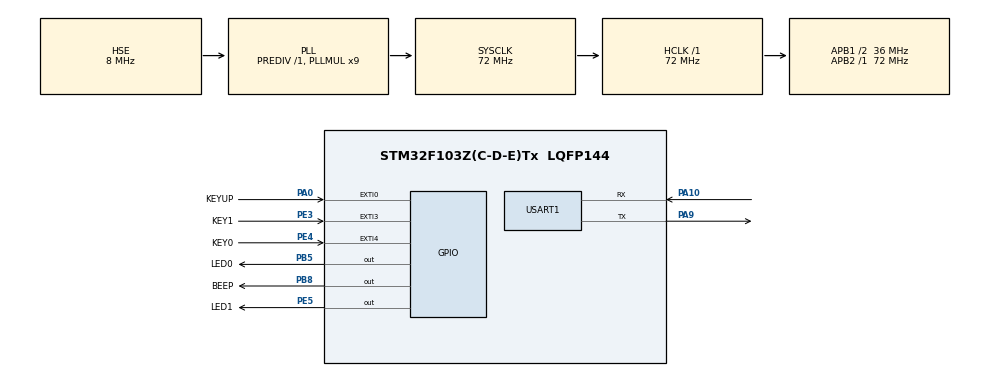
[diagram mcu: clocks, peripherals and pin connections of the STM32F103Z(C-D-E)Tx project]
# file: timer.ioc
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Mcu.Family=STM32F1
Mcu.Name=STM32F103Z(C-D-E)Tx
Mcu.Package=LQFP144
NVIC.EXTI0_IRQn=true\:1\:0\:true\:false\:true\:true\:true
NVIC.EXTI3_IRQn=true\:1\:0\:true\:false\:true\:true\:true
NVIC.EXTI4_IRQn=true\:1\:0\:true\:false\:true\:true\:true
NVIC.PriorityGroup=NVIC_PRIORITYGROUP_4
NVIC.TIM6_IRQn=true\:3\:0\:true\:false\:true\:true\:true
NVIC.TIM7_IRQn=true\:3\:0\:true\:false\:true\:true\:true
NVIC.USART1_IRQn=true\:0\:0\:false\:false\:true\:true\:true
OSC_IN.Mode=HSE-External-Oscillator
OSC_IN.Signal=RCC_OSC_IN
OSC_OUT.Mode=HSE-External-Oscillator
OSC_OUT.Signal=RCC_OSC_OUT
PA0-WKUP.GPIO_Label=KEYUP
PA0-WKUP.GPIO_ModeDefaultEXTI=GPIO_MODE_IT_RISING
PA0-WKUP.GPIO_PuPd=GPIO_PULLDOWN
PA0-WKUP.Signal=GPXTI0
PA10.Mode=Asynchronous
PA10.Signal=USART1_RX
PA13.Mode=Serial_Wire
PA13.Signal=SYS_JTMS-SWDIO
PA14.Mode=Serial_Wire
PA14.Signal=SYS_JTCK-SWCLK
PA9.Mode=Asynchronous
PA9.Signal=USART1_TX
PB5.GPIO_Label=LED0
PB5.PinState=GPIO_PIN_SET
PB5.Signal=GPIO_Output
PB8.GPIO_Label=BEEP
PB8.Signal=GPIO_Output
PE3.GPIO_Label=KEY1
PE3.GPIO_ModeDefaultEXTI=GPIO_MODE_IT_FALLING
PE3.GPIO_PuPd=GPIO_PULLUP
PE3.Signal=GPXTI3
PE4.GPIO_Label=KEY0
PE4.GPIO_ModeDefaultEXTI=GPIO_MODE_IT_FALLING
PE4.GPIO_PuPd=GPIO_PULLUP
PE4.Signal=GPXTI4
PE5.GPIO_Label=LED1
PE5.PinState=GPIO_PIN_SET
PE5.Signal=GPIO_Output
ProjectManager.HeapSize=0x200
ProjectManager.StackSize=0x400
ProjectManager.TargetToolchain=SW4STM32
RCC.AHBFreq_Value=72000000
RCC.APB1CLKDivider=RCC_HCLK_DIV2
RCC.APB1Freq_Value=36000000
RCC.APB1TimFreq_Value=72000000
RCC.APB2Freq_Value=72000000
RCC.APB2TimFreq_Value=72000000
RCC.HCLKFreq_Value=72000000
RCC.PLLMUL=RCC_PLL_MUL9
RCC.PLLSourceVirtual=RCC_PLLSOURCE_HSE
RCC.SYSCLKFreq_VALUE=72000000
RCC.SYSCLKSource=RCC_SYSCLKSOURCE_PLLCLK
RCC.USBFreq_Value=72000000
TIM6.AutoReloadPreload=TIM_AUTORELOAD_PRELOAD_DISABLE
TIM6.Period=10000-1
TIM6.Prescaler=7200-1
TIM7.AutoReloadPreload=TIM_AUTORELOAD_PRELOAD_DISABLE
TIM7.Period=5000-1
TIM7.Prescaler=7200-1
USART1.VirtualMode=VM_ASYNC
VP_TIM6_VS_ClockSourceINT.Mode=Enable_Timer
VP_TIM7_VS_ClockSourceINT.Mode=Enable_Timer
board=custom

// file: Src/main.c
/* USER CODE BEGIN Header */
/**
  ******************************************************************************
  * @file           : main.c
  * @brief          : Main program body
  ******************************************************************************
  * @attention
  *
  * <h2><center>&copy; Copyright (c) 2019 STMicroelectronics.
  * All rights reserved.</center></h2>
  *
  * This software component is licensed by ST under BSD 3-Clause license,
  * the "License"; You may not use this file except in compliance with the
  * License. You may obtain a copy of the License at:
  *                        opensource.org/licenses/BSD-3-Clause
  *
  ******************************************************************************
  */
/* USER CODE END Header */

#include "main.h"

TIM_HandleTypeDef htim6;
TIM_HandleTypeDef htim7;

UART_HandleTypeDef huart1;

void SystemClock_Config(void);
static void MX_GPIO_Init(void);
static void MX_TIM6_Init(void);
static void MX_TIM7_Init(void);
static void MX_USART1_UART_Init(void);

/* USER CODE BEGIN 0 */
void HAL_TIM_PeriodElapsedCallback(TIM_HandleTypeDef *htim)
{
    if (htim->Instance == htim6.Instance) {
        HAL_GPIO_TogglePin(LED0_GPIO_Port, LED0_Pin);
    }
    if (htim->Instance == htim7.Instance) {
        HAL_GPIO_TogglePin(LED1_GPIO_Port, LED1_Pin);
    }
}

/* USER CODE END 0 */

int main(void)
{

  /* MCU Configuration--------------------------------------------------------*/

  /* Reset of all peripherals, Initializes the Flash interface and the Systick. */
  HAL_Init();

  /* Configure the system clock */
  SystemClock_Config();

  /* Initialize all configured peripherals */
  MX_GPIO_Init();
  MX_TIM6_Init();
  MX_TIM7_Init();
  MX_USART1_UART_Init();
  /* USER CODE BEGIN 2 */
  HAL_TIM_Base_Start_IT(&htim6);
  HAL_TIM_Base_Start_IT(&htim7);

  /* USER CODE END 2 */

  /* Infinite loop */
  while (1)
  {

  }
}

void SystemClock_Config(void)
{
  RCC_OscInitTypeDef RCC_OscInitStruct = {0};
  RCC_ClkInitTypeDef RCC_ClkInitStruct = {0};

  /** Initializes the CPU, AHB and APB busses clocks
  */
  RCC_OscInitStruct.OscillatorType = RCC_OSCILLATORTYPE_HSE;
  RCC_OscInitStruct.HSEState = RCC_HSE_ON;
  RCC_OscInitStruct.HSEPredivValue = RCC_HSE_PREDIV_DIV1;
  RCC_OscInitStruct.HSIState = RCC_HSI_ON;
  RCC_OscInitStruct.PLL.PLLState = RCC_PLL_ON;
  RCC_OscInitStruct.PLL.PLLSource = RCC_PLLSOURCE_HSE;
  RCC_OscInitStruct.PLL.PLLMUL = RCC_PLL_MUL9;
  if (HAL_RCC_OscConfig(&RCC_OscInitStruct) != HAL_OK)
  {
    Error_Handler();
  }
  /** Initializes the CPU, AHB and APB busses clocks
  */
  RCC_ClkInitStruct.ClockType = RCC_CLOCKTYPE_HCLK|RCC_CLOCKTYPE_SYSCLK
                              |RCC_CLOCKTYPE_PCLK1|RCC_CLOCKTYPE_PCLK2;
  RCC_ClkInitStruct.SYSCLKSource = RCC_SYSCLKSOURCE_PLLCLK;
  RCC_ClkInitStruct.AHBCLKDivider = RCC_SYSCLK_DIV1;
  RCC_ClkInitStruct.APB1CLKDivider = RCC_HCLK_DIV2;
  RCC_ClkInitStruct.APB2CLKDivider = RCC_HCLK_DIV1;

  if (HAL_RCC_ClockConfig(&RCC_ClkInitStruct, FLASH_LATENCY_2) != HAL_OK)
  {
    Error_Handler();
  }
}

static void MX_TIM6_Init(void)
{

  TIM_MasterConfigTypeDef sMasterConfig = {0};

  htim6.Instance = TIM6;
  htim6.Init.Prescaler = 7200-1;
  htim6.Init.CounterMode = TIM_COUNTERMODE_UP;
  htim6.Init.Period = 10000-1;
  htim6.Init.AutoReloadPreload = TIM_AUTORELOAD_PRELOAD_DISABLE;
  if (HAL_TIM_Base_Init(&htim6) != HAL_OK)
  {
    Error_Handler();
  }
  sMasterConfig.MasterOutputTrigger = TIM_TRGO_RESET;
  sMasterConfig.MasterSlaveMode = TIM_MASTERSLAVEMODE_DISABLE;
  if (HAL_TIMEx_MasterConfigSynchronization(&htim6, &sMasterConfig) != HAL_OK)
  {
    Error_Handler();
  }

}

static void MX_TIM7_Init(void)
{

  TIM_MasterConfigTypeDef sMasterConfig = {0};

  htim7.Instance = TIM7;
  htim7.Init.Prescaler = 7200-1;
  htim7.Init.CounterMode = TIM_COUNTERMODE_UP;
  htim7.Init.Period = 5000-1;
  htim7.Init.AutoReloadPreload = TIM_AUTORELOAD_PRELOAD_DISABLE;
  if (HAL_TIM_Base_Init(&htim7) != HAL_OK)
  {
    Error_Handler();
  }
  sMasterConfig.MasterOutputTrigger = TIM_TRGO_RESET;
  sMasterConfig.MasterSlaveMode = TIM_MASTERSLAVEMODE_DISABLE;
  if (HAL_TIMEx_MasterConfigSynchronization(&htim7, &sMasterConfig) != HAL_OK)
  {
    Error_Handler();
  }

}

static void MX_USART1_UART_Init(void)
{

  huart1.Instance = USART1;
  huart1.Init.BaudRate = 115200;
  huart1.Init.WordLength = UART_WORDLENGTH_8B;
  huart1.Init.StopBits = UART_STOPBITS_1;
  huart1.Init.Parity = UART_PARITY_NONE;
  huart1.Init.Mode = UART_MODE_TX_RX;
  huart1.Init.HwFlowCtl = UART_HWCONTROL_NONE;
  huart1.Init.OverSampling = UART_OVERSAMPLING_16;
  if (HAL_UART_Init(&huart1) != HAL_OK)
  {
    Error_Handler();
  }

}

static void MX_GPIO_Init(void)
{
  GPIO_InitTypeDef GPIO_InitStruct = {0};

  /* GPIO Ports Clock Enable */
  __HAL_RCC_GPIOE_CLK_ENABLE();
  __HAL_RCC_GPIOA_CLK_ENABLE();
  __HAL_RCC_GPIOB_CLK_ENABLE();

  /*Configure GPIO pin Output Level */
  HAL_GPIO_WritePin(LED1_GPIO_Port, LED1_Pin, GPIO_PIN_SET);

  /*Configure GPIO pin Output Level */
  HAL_GPIO_WritePin(LED0_GPIO_Port, LED0_Pin, GPIO_PIN_SET);

  /*Configure GPIO pin Output Level */
  HAL_GPIO_WritePin(BEEP_GPIO_Port, BEEP_Pin, GPIO_PIN_RESET);

  /*Configure GPIO pins : KEY1_Pin KEY0_Pin */
  GPIO_InitStruct.Pin = KEY1_Pin|KEY0_Pin;
  GPIO_InitStruct.Mode = GPIO_MODE_IT_FALLING;
  GPIO_InitStruct.Pull = GPIO_PULLUP;
  HAL_GPIO_Init(GPIOE, &GPIO_InitStruct);

  /*Configure GPIO pin : LED1_Pin */
  GPIO_InitStruct.Pin = LED1_Pin;
  GPIO_InitStruct.Mode = GPIO_MODE_OUTPUT_PP;
  GPIO_InitStruct.Pull = GPIO_NOPULL;
  GPIO_InitStruct.Speed = GPIO_SPEED_FREQ_LOW;
  HAL_GPIO_Init(LED1_GPIO_Port, &GPIO_InitStruct);

  /*Configure GPIO pin : KEYUP_Pin */
  GPIO_InitStruct.Pin = KEYUP_Pin;
  GPIO_InitStruct.Mode = GPIO_MODE_IT_RISING;
  GPIO_InitStruct.Pull = GPIO_PULLDOWN;
  HAL_GPIO_Init(KEYUP_GPIO_Port, &GPIO_InitStruct);

  /*Configure GPIO pins : LED0_Pin BEEP_Pin */
  GPIO_InitStruct.Pin = LED0_Pin|BEEP_Pin;
  GPIO_InitStruct.Mode = GPIO_MODE_OUTPUT_PP;
  GPIO_InitStruct.Pull = GPIO_NOPULL;
  GPIO_InitStruct.Speed = GPIO_SPEED_FREQ_LOW;
  HAL_GPIO_Init(GPIOB, &GPIO_InitStruct);

  /* EXTI interrupt init*/
  HAL_NVIC_SetPriority(EXTI0_IRQn, 1, 0);
  HAL_NVIC_EnableIRQ(EXTI0_IRQn);

  HAL_NVIC_SetPriority(EXTI3_IRQn, 1, 0);
  HAL_NVIC_EnableIRQ(EXTI3_IRQn);

  HAL_NVIC_SetPriority(EXTI4_IRQn, 1, 0);
  HAL_NVIC_EnableIRQ(EXTI4_IRQn);

}

void Error_Handler(void)
{
}

/************************ (C) COPYRIGHT STMicroelectronics *****END OF FILE****/
